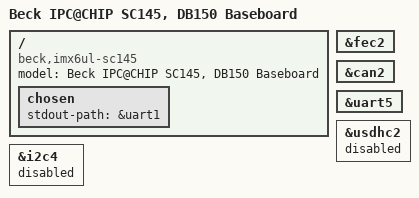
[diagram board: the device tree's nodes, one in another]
/*
 * Copyright (C) 2015 Freescale Semiconductor, Inc.
 * Copyright (C) 2016 Beck IPC GmbH
 * Copyright (C) 2017 Kernel Concepts GmbH
 *
 * This program is free software; you can redistribute it and/or modify
 * it under the terms of the GNU General Public License version 2 as
 * published by the Free Software Foundation.
 */

/* Device tree for SC145-H02 on DB150-H01 */

/dts-v1/;
#include "imx6ul.dtsi"
#include "imx6ul-sc145-h02.dtsi"

/ {
    model = "Beck IPC@CHIP SC145, DB150 Baseboard";
    compatible = "beck,imx6ul-sc145", "fsl,imx6ul";

    chosen {
        stdout-path = &uart1;
    };
};


&fec2 {
    status = "okay";
};

&can2 {
    status = "okay";
};

&uart5 {
    status = "okay";
};

&usdhc2 {
    status = "disabled";
};

&i2c4 {
    status = "disabled";
};
